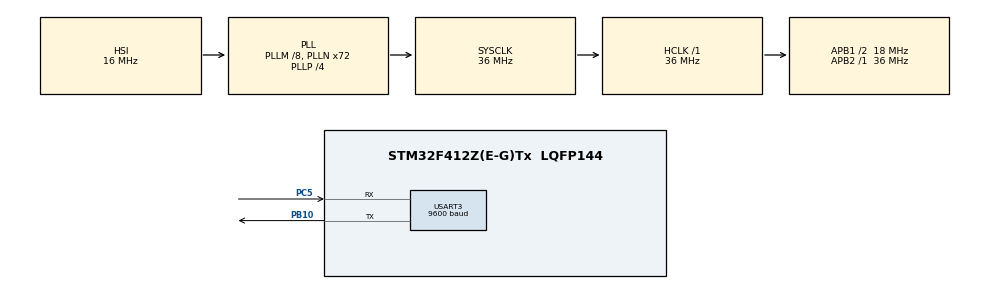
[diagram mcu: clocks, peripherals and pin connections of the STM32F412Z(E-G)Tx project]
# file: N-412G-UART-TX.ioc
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Dma.Request0=USART3_TX
Dma.USART3_TX.0.Direction=DMA_MEMORY_TO_PERIPH
Dma.USART3_TX.0.FIFOMode=DMA_FIFOMODE_DISABLE
Dma.USART3_TX.0.Instance=DMA1_Stream3
Dma.USART3_TX.0.MemDataAlignment=DMA_MDATAALIGN_BYTE
Dma.USART3_TX.0.MemInc=DMA_MINC_ENABLE
Dma.USART3_TX.0.Mode=DMA_NORMAL
Dma.USART3_TX.0.PeriphDataAlignment=DMA_PDATAALIGN_BYTE
Dma.USART3_TX.0.PeriphInc=DMA_PINC_DISABLE
Dma.USART3_TX.0.Priority=DMA_PRIORITY_LOW
Mcu.Family=STM32F4
Mcu.Name=STM32F412Z(E-G)Tx
Mcu.Package=LQFP144
NVIC.DMA1_Stream3_IRQn=true\:0\:0\:false\:false\:true\:false\:true\:true
NVIC.PriorityGroup=NVIC_PRIORITYGROUP_4
NVIC.TIM2_IRQn=true\:0\:0\:false\:false\:true\:true\:true\:true
NVIC.USART3_IRQn=true\:0\:0\:false\:false\:true\:true\:true\:true
PA13.Mode=Serial_Wire
PA13.Signal=SYS_JTMS-SWDIO
PA14.Mode=Serial_Wire
PA14.Signal=SYS_JTCK-SWCLK
PB10.Mode=Asynchronous
PB10.Signal=USART3_TX
PC5.Mode=Asynchronous
PC5.Signal=USART3_RX
ProjectManager.HeapSize=0x200
ProjectManager.StackSize=0x400
ProjectManager.TargetToolchain=STM32CubeIDE
RCC.48MHZClocksFreq_Value=48000000
RCC.AHBFreq_Value=36000000
RCC.APB1CLKDivider=RCC_HCLK_DIV2
RCC.APB1Freq_Value=18000000
RCC.APB1TimFreq_Value=36000000
RCC.APB2Freq_Value=36000000
RCC.APB2TimFreq_Value=36000000
RCC.CortexFreq_Value=36000000
RCC.HCLKFreq_Value=36000000
RCC.HSE_VALUE=8000000
RCC.HSI_VALUE=16000000
RCC.PLLI2SM=4
RCC.PLLI2SN=50
RCC.PLLM=8
RCC.PLLN=72
RCC.PLLP=RCC_PLLP_DIV4
RCC.PLLQ=3
RCC.SYSCLKFreq_VALUE=36000000
RCC.SYSCLKSource=RCC_SYSCLKSOURCE_PLLCLK
RCC.USBFreq_Value=48000000
RCC.VCOOutputFreq_Value=144000000
TIM2.Period=501-1
TIM2.Prescaler=16000
USART3.BaudRate=9600
USART3.VirtualMode=VM_ASYNC
VP_TIM2_VS_ClockSourceINT.Mode=Internal
board=STM32F412G-DISCO

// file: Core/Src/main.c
/* USER CODE BEGIN Header */
/**
  ******************************************************************************
  * @file           : main.c
  * @brief          : Main program body
  ******************************************************************************
  * @attention
  *
  * Copyright (c) 2024 STMicroelectronics.
  * All rights reserved.
  *
  * This software is licensed under terms that can be found in the LICENSE file
  * in the root directory of this software component.
  * If no LICENSE file comes with this software, it is provided AS-IS.
  *
  ******************************************************************************
  */
/* USER CODE END Header */
#include "main.h"

/* USER CODE BEGIN Includes */
sensor_status_handle_TypeDef sensor_handle = { 0,0,0,0,0,0,0,0,0,0 };
/* USER CODE END Includes */

/* USER CODE BEGIN PTD */
uint8_t Timer2Int = 0;
UART_HandleTypeDef UartHandle;
__IO ITStatus UartReady = RESET;
/* USER CODE END PTD */

TIM_HandleTypeDef htim2;

UART_HandleTypeDef huart3;
DMA_HandleTypeDef hdma_usart3_tx;

void SystemClock_Config(void);
static void MX_GPIO_Init(void);
static void MX_DMA_Init(void);
static void MX_USART3_UART_Init(void);
static void MX_TIM2_Init(void);
/* USER CODE BEGIN PFP */
void TXdata(void)
{
	char ID[6] = {0};
	char data[5] = {0};
	char packet[11] = {0};

	sensor_handle.Sensor1 = 100;
	sensor_handle.Sensor2 = 100;
	sensor_handle.Sensor3 = 100;
	sensor_handle.Sensor4 = 100;
	sensor_handle.Sensor5 = 100;
	sensor_handle.Sensor6 = 100;
	sensor_handle.Sensor7 = 100;
	sensor_handle.Sensor8 = 100;
	sensor_handle.Sensor9 = 100;
	sensor_handle.Sensor10 = 100;

	if(Timer2Int == 1)
	{

		//SPD L1 SPD Earth
		{
		  // SPD Type
		  sprintf(ID, "%s", "SENS01"); // convert ID into value
		  sprintf(data, "%05d", sensor_handle.Sensor1); // convert data into string in "00000" format (5 digit)
		  sprintf(packet, "%s%s", ID, data); // combine str2 to str1
	      if((HAL_UART_Transmit_DMA(&huart3,  packet, sizeof(packet))!= HAL_OK))
	    		  {
	    	  Error_Handler();
	      	 	   }

	      while (UartReady != SET)
	      {
	      }

	      UartReady = RESET;
		}

		HAL_Delay(20);

	//SPD Type Packet Send

	{
	  // SPD Type
	  sprintf(ID, "%s", "SENS02"); // convert ID into value
	  sprintf(data, "%05d", sensor_handle.Sensor2); // convert data into string in "00000" format (5 digit)
	  sprintf(packet, "%s%s", ID, data); // combine str2 to str1
      if((HAL_UART_Transmit_DMA(&huart3,  packet, sizeof(packet))!= HAL_OK))
    		  {
    	  Error_Handler();
      	 	   }
            while (UartReady != SET)
      {
      }

      UartReady = RESET;
	}
	HAL_Delay(20);

	//SPD L1 SPD Neutral
	{
	  // SPD Type
	  sprintf(ID, "%s", "SENS03"); // convert ID into value
	  sprintf(data, "%05d", sensor_handle.Sensor3); // convert data into string in "00000" format (5 digit)
	  sprintf(packet, "%s%s", ID, data); // combine str2 to str1
      if((HAL_UART_Transmit_DMA(&huart3,  packet, sizeof(packet))!= HAL_OK))
    		  {
    	  Error_Handler();
      	 	   }

      while (UartReady != SET)
      {
      }

      UartReady = RESET;
	}
	HAL_Delay(20);
	//SPD L2 SPD Neutral
	{
	  // SPD Type
	  sprintf(ID, "%s", "SENS04"); // convert ID into value
	  sprintf(data, "%05d", sensor_handle.Sensor4); // convert data into string in "00000" format (5 digit)
	  sprintf(packet, "%s%s", ID, data); // combine str2 to str1
      if((HAL_UART_Transmit_DMA(&huart3,  packet, sizeof(packet))!= HAL_OK))
    		  {
    	  Error_Handler();
      	 	   }

      while (UartReady != SET)
      {
      }

      UartReady = RESET;
	}
	HAL_Delay(20);
	//SPD L3 SPD Neutral
	{
	  // SPD Type
	  sprintf(ID, "%s", "SENS05"); // convert ID into value
	  sprintf(data, "%05d", sensor_handle.Sensor5); // convert data into string in "00000" format (5 digit)
	  sprintf(packet, "%s%s", ID, data); // combine str2 to str1
      if((HAL_UART_Transmit_DMA(&huart3,  packet, sizeof(packet))!= HAL_OK))
    		  {
    	  Error_Handler();
      	 	   }

      while (UartReady != SET)
      {
      }

      UartReady = RESET;
	}
	HAL_Delay(20);

	//SPD L2SPD Earth
	{
	  // SPD Type
	  sprintf(ID, "%s", "SENS06"); // convert ID into value
	  sprintf(data, "%05d", sensor_handle.Sensor6); // convert data into string in "00000" format (5 digit)
	  sprintf(packet, "%s%s", ID, data); // combine str2 to str1
      if((HAL_UART_Transmit_DMA(&huart3,  packet, sizeof(packet))!= HAL_OK))
    		  {
    	  Error_Handler();
      	 	   }

      while (UartReady != SET)
      {
      }

      UartReady = RESET;
	}
	HAL_Delay(20);
	//SPD L3SPD Earth
	{
	  // SPD Type
	  sprintf(ID, "%s", "SENS07"); // convert ID into value
	  sprintf(data, "%05d", sensor_handle.Sensor7); // convert data into string in "00000" format (5 digit)
	  sprintf(packet, "%s%s", ID, data); // combine str2 to str1
      if((HAL_UART_Transmit_DMA(&huart3,  packet, sizeof(packet))!= HAL_OK))
    		  {
    	  Error_Handler();
      	 	   }

      while (UartReady != SET)
      {
      }

      UartReady = RESET;
	}
	HAL_Delay(20);
	//SPD NE1SPD
	{
	  // SPD Type
	  sprintf(ID, "%s", "SENS08"); // convert ID into value
	  sprintf(data, "%05d", sensor_handle.Sensor8); // convert data into string in "00000" format (5 digit)
	  sprintf(packet, "%s%s", ID, data); // combine str2 to str1
      if((HAL_UART_Transmit_DMA(&huart3,  packet, sizeof(packet))!= HAL_OK))
    		  {
    	  Error_Handler();
      	 	   }

      while (UartReady != SET)
      {
      }

      UartReady = RESET;
	}
	HAL_Delay(20);
	//SPD V1 Voltage
	{
	  // SPD Type
	  sprintf(ID, "%s", "SENS09"); // convert ID into value
	  sprintf(data, "%05d", sensor_handle.Sensor9); // convert data into string in "00000" format (5 digit)
	  sprintf(packet, "%s%s", ID, data); // combine str2 to str1
      if((HAL_UART_Transmit_DMA(&huart3,  packet, sizeof(packet))!= HAL_OK))
    		  {
    	  Error_Handler();
      	 	   }

      while (UartReady != SET)
      {
      }

      UartReady = RESET;
	}
	HAL_Delay(20);
	//SPD V2 Voltage
	{
	  // SPD Type
	  sprintf(ID, "%s", "SENS10"); // convert ID into value
	  sprintf(data, "%05d", sensor_handle.Sensor10); // convert data into string in "00000" format (5 digit)
	  sprintf(packet, "%s%s", ID, data); // combine str2 to str1
      if((HAL_UART_Transmit_DMA(&huart3,  packet, sizeof(packet))!= HAL_OK))
    		  {
    	  Error_Handler();
      	 	   }

      while (UartReady != SET)
      {
      }

      UartReady = RESET;
	}

	}

	Timer2Int = 0;
}

/* USER CODE END PFP */

int main(void)
{

  /* MCU Configuration--------------------------------------------------------*/

  /* Reset of all peripherals, Initializes the Flash interface and the Systick. */
  HAL_Init();

  /* Configure the system clock */
  SystemClock_Config();

  /* Initialize all configured peripherals */
  MX_GPIO_Init();
  MX_DMA_Init();
  MX_USART3_UART_Init();
  MX_TIM2_Init();

  /* Infinite loop */
  while (1)
  {

    /* USER CODE BEGIN 3 */
	HAL_TIM_Base_Start_IT(&htim2);
    TXdata();

  }
  /* USER CODE END 3 */
}

void SystemClock_Config(void)
{
  RCC_OscInitTypeDef RCC_OscInitStruct = {0};
  RCC_ClkInitTypeDef RCC_ClkInitStruct = {0};

  /** Configure the main internal regulator output voltage
  */
  __HAL_RCC_PWR_CLK_ENABLE();
  __HAL_PWR_VOLTAGESCALING_CONFIG(PWR_REGULATOR_VOLTAGE_SCALE1);

  /** Initializes the RCC Oscillators according to the specified parameters
  * in the RCC_OscInitTypeDef structure.
  */
  RCC_OscInitStruct.OscillatorType = RCC_OSCILLATORTYPE_HSI;
  RCC_OscInitStruct.HSIState = RCC_HSI_ON;
  RCC_OscInitStruct.HSICalibrationValue = RCC_HSICALIBRATION_DEFAULT;
  RCC_OscInitStruct.PLL.PLLState = RCC_PLL_ON;
  RCC_OscInitStruct.PLL.PLLSource = RCC_PLLSOURCE_HSI;
  RCC_OscInitStruct.PLL.PLLM = 8;
  RCC_OscInitStruct.PLL.PLLN = 72;
  RCC_OscInitStruct.PLL.PLLP = RCC_PLLP_DIV4;
  RCC_OscInitStruct.PLL.PLLQ = 3;
  RCC_OscInitStruct.PLL.PLLR = 2;
  if (HAL_RCC_OscConfig(&RCC_OscInitStruct) != HAL_OK)
  {
    Error_Handler();
  }

  /** Initializes the CPU, AHB and APB buses clocks
  */
  RCC_ClkInitStruct.ClockType = RCC_CLOCKTYPE_HCLK|RCC_CLOCKTYPE_SYSCLK
                              |RCC_CLOCKTYPE_PCLK1|RCC_CLOCKTYPE_PCLK2;
  RCC_ClkInitStruct.SYSCLKSource = RCC_SYSCLKSOURCE_PLLCLK;
  RCC_ClkInitStruct.AHBCLKDivider = RCC_SYSCLK_DIV1;
  RCC_ClkInitStruct.APB1CLKDivider = RCC_HCLK_DIV2;
  RCC_ClkInitStruct.APB2CLKDivider = RCC_HCLK_DIV1;

  if (HAL_RCC_ClockConfig(&RCC_ClkInitStruct, FLASH_LATENCY_1) != HAL_OK)
  {
    Error_Handler();
  }
}

static void MX_TIM2_Init(void)
{

  TIM_ClockConfigTypeDef sClockSourceConfig = {0};
  TIM_MasterConfigTypeDef sMasterConfig = {0};

  htim2.Instance = TIM2;
  htim2.Init.Prescaler = 16000;
  htim2.Init.CounterMode = TIM_COUNTERMODE_UP;
  htim2.Init.Period = 501-1;
  htim2.Init.ClockDivision = TIM_CLOCKDIVISION_DIV1;
  htim2.Init.AutoReloadPreload = TIM_AUTORELOAD_PRELOAD_DISABLE;
  if (HAL_TIM_Base_Init(&htim2) != HAL_OK)
  {
    Error_Handler();
  }
  sClockSourceConfig.ClockSource = TIM_CLOCKSOURCE_INTERNAL;
  if (HAL_TIM_ConfigClockSource(&htim2, &sClockSourceConfig) != HAL_OK)
  {
    Error_Handler();
  }
  sMasterConfig.MasterOutputTrigger = TIM_TRGO_RESET;
  sMasterConfig.MasterSlaveMode = TIM_MASTERSLAVEMODE_DISABLE;
  if (HAL_TIMEx_MasterConfigSynchronization(&htim2, &sMasterConfig) != HAL_OK)
  {
    Error_Handler();
  }

}

static void MX_USART3_UART_Init(void)
{

  huart3.Instance = USART3;
  huart3.Init.BaudRate = 9600;
  huart3.Init.WordLength = UART_WORDLENGTH_8B;
  huart3.Init.StopBits = UART_STOPBITS_1;
  huart3.Init.Parity = UART_PARITY_NONE;
  huart3.Init.Mode = UART_MODE_TX_RX;
  huart3.Init.HwFlowCtl = UART_HWCONTROL_NONE;
  huart3.Init.OverSampling = UART_OVERSAMPLING_16;
  if (HAL_UART_Init(&huart3) != HAL_OK)
  {
    Error_Handler();
  }

}

static void MX_DMA_Init(void)
{

  /* DMA controller clock enable */
  __HAL_RCC_DMA1_CLK_ENABLE();

  /* DMA interrupt init */
  /* DMA1_Stream3_IRQn interrupt configuration */
  HAL_NVIC_SetPriority(DMA1_Stream3_IRQn, 0, 0);
  HAL_NVIC_EnableIRQ(DMA1_Stream3_IRQn);

}

static void MX_GPIO_Init(void)
{

  /* GPIO Ports Clock Enable */
  __HAL_RCC_GPIOC_CLK_ENABLE();
  __HAL_RCC_GPIOB_CLK_ENABLE();
  __HAL_RCC_GPIOA_CLK_ENABLE();

}

/* USER CODE BEGIN 4 */

void HAL_TIM_PeriodElapsedCallback(TIM_HandleTypeDef *htim)
{
	 if (htim->Instance == TIM2) // 1 second timer
	 {
		 Timer2Int = 1;
	 }

 }
void HAL_UART_TxCpltCallback(UART_HandleTypeDef *UartHandle)
{
  /* Set transmission flag: trasfer complete*/
  UartReady = SET;
}
/* USER CODE END 4 */

void Error_Handler(void)
{
  __disable_irq();
  while (1)
  {
  }
}
